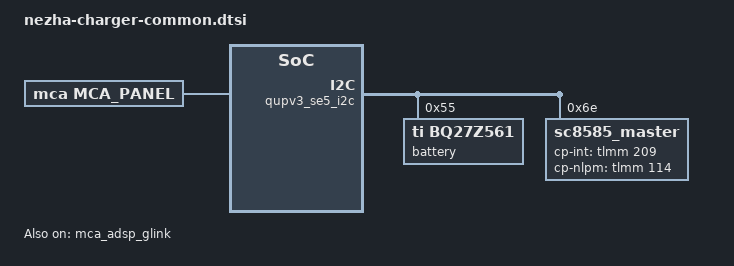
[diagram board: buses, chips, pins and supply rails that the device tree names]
// SPDX-License-Identifier: GPL-2.0-only

#include "nezha-sc96281.dtsi"

&soc {
	mca_charge_interface: mca_charge_interface {
		compatible = "mca,charge_interface";
		status = "okay";
	};

	/* Tables match MiCode kernel_devicetree@396596c6 Nezha exactly.
	 * Remain disabled until policy, voters and protection are integrated.
	 */
	mca_charger_thermal: mca_charger_thermal {
		compatible = "mca_charger_thermal";
		status = "disabled";
		support_wireless = <1>;
		xiaomi,wireless-thermal-columns = <11>;
		wired_thermal = <
			1900 1500 1900 3000 13500 13500 13500 13500 13500 13500
			1900 1500 1900 3000 11000 11000 11000 11000 11000 11000
			1900 1500 1900 3000 9000 9000 9000 9000 9000 9000
			1900 1450 1900 3000 8000 8000 8000 8000 8000 8000
			1900 1400 1900 3000 7000 7000 7000 7000 7000 7000
			1900 1350 1900 2800 6000 6000 6000 6000 6000 6000
			1900 1300 1900 2600 5000 5000 5000 5000 5000 5000
			1900 1150 1900 2310 4000 4000 4000 4000 4000 4000
			1700 1100 1700 2200 3500 3500 3500 3500 3500 3500
			1600 1000 1600 2000 3000 3000 3000 3000 3000 3000
			1400 900 1500 2000 2500 2500 2500 2500 2500 2500
			1200 850 1500 2000 2000 2000 2000 2000 2000 2000
			1100 750 1500 1500 1500 1500 1500 1500 1500 1500
			1100 650 1000 1000 1000 1000 1000 1000 1000 1000
			1100 600 500 500 500 500 500 500 500 500
		>;
		wireless_thermal = <
			850 1000 1100 900 3400 4400 9000 9000 2200 3500 4400
			850 1000 1100 750 3200 4200 8000 8000 2200 3300 4200
			850 1000 1100 650 2200 3400 7000 7000 1000 3000 3400
			700 1000 1100 650 1800 2800 6000 6000 1000 2300 2800
			700 1000 700 650 1500 2600 5000 5000 800 2000 2600
			500 1000 700 650 1300 2200 4000 4000 800 1800 2200
			500 700 600 400 1100 2200 3500 3500 700 1600 2200
			500 700 600 400 1000 1800 3000 3000 700 1500 1800
			500 500 500 300 800 1100 2500 2500 600 1100 1100
			400 500 500 300 700 1000 2000 2000 600 1000 1000
			400 500 500 250 600 800 1500 1500 500 800 800
			400 500 500 250 500 700 1000 1000 500 700 700
			300 500 500 250 500 600 800 800 400 600 600
			300 400 400 200 400 500 500 500 400 500 500
			300 300 300 150 300 400 400 400 300 400 400
		>;
	};

	mca_fg_psy: fuel-gauge-bridge {
		compatible = "xiaomi,nezha-fg-psy";
		power-supplies = <&nezha_fuel_gauge>;
		status = "okay";
	};

	mca_qcom_subpmic_proxy: mca_qcom_subpmic_proxy {
		compatible = "mca,qcom_subpmic";
		status = "okay";
	};

	mca_panel: mca_panel {
		compatible = "mca,mca_panel";
		status = "ok";
	};

	mca_bc12_class: mca_bc12_class {
		compatible = "mca,bc12_class";
		status = "ok";
	};

	mca_protocol_core: mca_protocol_core {
		compatible = "mca,protocol_core";
		status = "ok";
	};

	mca_protocol_pd_class: mca_protocol_pd_class {
		compatible = "mca,protocol_pd";
		status = "ok";
		support_mode = <4>;
		max_power = <90>;
	};

	mca_qcom_pd_protocol: mca_qcom_pd_protocol {
		compatible = "mca,adsp_pd_protocol";
		status = "ok";
	};

	mca_protocol_qc_class: mca_protocol_qc_class {
		compatible = "mca,protocol_qc";
		status = "ok";
	};

	mca_platform_cp: mca_platform_cp {
		compatible = "mca,platform_cp";
		status = "ok";
		cp-num = <1>;
		cp-dir-list = "cp_master";
	};

	mca_platform_loadsw: mca_platform_loadsw {
		compatible = "mca,platform_loadsw";
		status = "disabled";
		loadsw-num = <1>;
		loadsw-dir-list = "loadsw_master";
	};
};

/* Both chargers claim PMIC GLINK owner 0x800a. Nezha uses MCA. */
&battery_charger {
	status = "disabled";
};

&mca_adsp_glink {
	status = "ok";
};

&tlmm {
	charger_cp_nlpm_default: charger_cp_nlpm_default {
		mux {
			pins = "gpio114";
			function = "gpio";
		};

		config {
			pins = "gpio114";
			drive-strength = <2>;
			bias-disable;
		};
	};

	charger_cp_int_default: charger_cp_int_default {
		mux {
			pins = "gpio209";
			function = "gpio";
		};

		config {
			pins = "gpio209";
			drive-strength = <2>;
			bias-disable;
		};
	};
};

&qupv3_se5_i2c {
	#address-cells = <1>;
	#size-cells = <0>;
	status = "okay";

	nezha_fuel_gauge: fuel-gauge@55 {
		compatible = "ti,bq27z561";
		reg = <0x55>;
		label = "battery";
	};

	sc8585_master@6e {
		compatible = "sc8585_master";
		reg = <0x6e>;
		ic_role = <0>;
		cp-int = <&tlmm 209 0>;
		cp-nlpm-gpio = <&tlmm 114 0>;
		pinctrl-names = "default";
		pinctrl-0 = <&charger_cp_nlpm_default &charger_cp_int_default>;
		bat-ovp-threshold = <4700>;
		bat-ovp-alarm-threshold = <4650>;
		bus-ovp-threshold = <21000 12000 6000>;
		usb-ovp-threshold = <21000 14000 7500>;
		bus-ocp-threshold = <5000 5600 5000>;
		wpc-ovp-threshold = <21000>;
		out-ovp-threshold = <5000>;
		pmid2-uvp-threshold = <350 350 100>;
		pmid2-ovp-threshold = <600>;
	};
};
